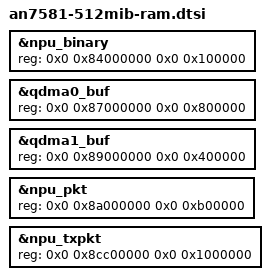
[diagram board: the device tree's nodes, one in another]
&npu_binary {
    reg = <0x0 0x84000000 0x0 0x100000>;   /* 1MB */
};

&qdma0_buf {
    reg = <0x0 0x87000000 0x0 0x800000>;   /* 8MB */
};

&qdma1_buf {
    reg = <0x0 0x89000000 0x0 0x400000>;   /* 4MB */
};

&npu_pkt {
    reg = <0x0 0x8a000000 0x0 0xb00000>;   /* 11MB */
};

&npu_txpkt {
    reg = <0x0 0x8cc00000 0x0 0x1000000>;  /* 16MB */
};
